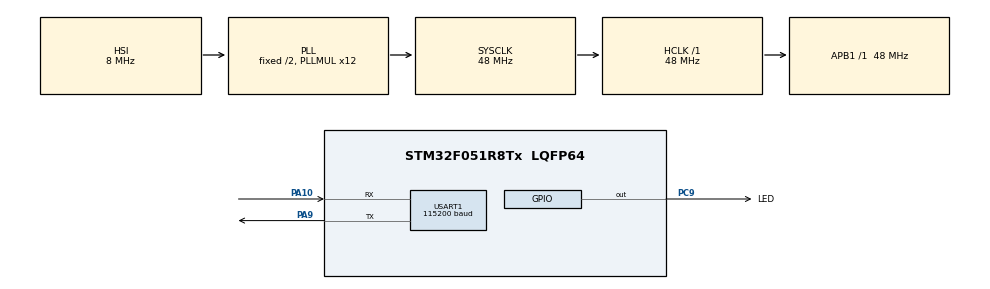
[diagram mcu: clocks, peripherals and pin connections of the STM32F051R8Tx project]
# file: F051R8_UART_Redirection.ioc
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Mcu.Family=STM32F0
PA10.Mode=Asynchronous
PC9.GPIO_Label=LED
USART1.BaudRate=115200
PA14.GPIO_Label=SWCLK
RCC.SYSCLKSource=RCC_SYSCLKSOURCE_PLLCLK
ProjectManager.StackSize=0x400
USART1.VirtualMode-Asynchronous=VM_ASYNC
PA13.Signal=SYS_SWDIO
PA9.Mode=Asynchronous
ProjectManager.TargetToolchain=STM32CubeIDE
RCC.HCLKFreq_Value=48000000
PA9.Signal=USART1_TX
RCC.AHBFreq_Value=48000000
board=STM32F0DISCOVERY
RCC.PLLMUL=RCC_PLL_MUL12
PA14.Mode=Serial_Wire
PA13.Mode=Serial_Wire
Mcu.Name=STM32F051R8Tx
PA13.GPIO_Label=SWDIO
RCC.SYSCLKFreq_VALUE=48000000
Mcu.Package=LQFP64
PA10.Signal=USART1_RX
PA14.Signal=SYS_SWCLK
ProjectManager.HeapSize=0x200
RCC.APB1TimFreq_Value=48000000
PC9.Signal=GPIO_Output
RCC.APB1Freq_Value=48000000

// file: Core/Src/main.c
/* USER CODE BEGIN Header */
/**
  ******************************************************************************
  * @file           : main.c
  * @brief          : Main program body
  ******************************************************************************
  * @attention
  *
  * <h2><center>&copy; Copyright (c) 2021 STMicroelectronics.
  * All rights reserved.</center></h2>
  *
  * This software component is licensed by ST under BSD 3-Clause license,
  * the "License"; You may not use this file except in compliance with the
  * License. You may obtain a copy of the License at:
  *                        opensource.org/licenses/BSD-3-Clause
  *
  ******************************************************************************
  */
/* USER CODE END Header */
#include "main.h"

/* USER CODE BEGIN Includes */
#include <stdio.h>
#include <string.h>
#include "uart_redirection.h"
/* USER CODE END Includes */

UART_HandleTypeDef huart1;

/* USER CODE BEGIN PV */
unsigned char counter = 0;
unsigned char max = 255;
/* USER CODE END PV */

void SystemClock_Config(void);
static void MX_GPIO_Init(void);
static void MX_USART1_UART_Init(void);

int main(void)
{
  /* USER CODE BEGIN 1 */
  int imax = 255;
  /* USER CODE END 1 */

  /* MCU Configuration--------------------------------------------------------*/

  /* Reset of all peripherals, Initializes the Flash interface and the Systick. */
  HAL_Init();

  /* Configure the system clock */
  SystemClock_Config();

  /* Initialize all configured peripherals */
  MX_GPIO_Init();
  MX_USART1_UART_Init();
  /* USER CODE BEGIN 2 */
  Set_UART_Redirection_Port(&huart1);
  /* USER CODE END 2 */

  /* Infinite loop */
  /* USER CODE BEGIN WHILE */
  printf("Set max counter: ");
  scanf("%d", &imax);
  max = (unsigned char)imax;
  printf("Count to %d\n\r", max);
  while (1) {
    printf("counter=%03d\n\r", counter++);
    if (counter > (char) max) {
      counter = 0;
    }
    HAL_GPIO_TogglePin(LED_GPIO_Port, LED_Pin);
    HAL_Delay(500);
    /* USER CODE END WHILE */

  }
}

void SystemClock_Config(void)
{
  RCC_OscInitTypeDef RCC_OscInitStruct = {0};
  RCC_ClkInitTypeDef RCC_ClkInitStruct = {0};
  RCC_PeriphCLKInitTypeDef PeriphClkInit = {0};

  /** Initializes the RCC Oscillators according to the specified parameters
  * in the RCC_OscInitTypeDef structure.
  */
  RCC_OscInitStruct.OscillatorType = RCC_OSCILLATORTYPE_HSI;
  RCC_OscInitStruct.HSIState = RCC_HSI_ON;
  RCC_OscInitStruct.HSICalibrationValue = RCC_HSICALIBRATION_DEFAULT;
  RCC_OscInitStruct.PLL.PLLState = RCC_PLL_ON;
  RCC_OscInitStruct.PLL.PLLSource = RCC_PLLSOURCE_HSI;
  RCC_OscInitStruct.PLL.PLLMUL = RCC_PLL_MUL12;
  RCC_OscInitStruct.PLL.PREDIV = RCC_PREDIV_DIV1;
  if (HAL_RCC_OscConfig(&RCC_OscInitStruct) != HAL_OK)
  {
    Error_Handler();
  }
  /** Initializes the CPU, AHB and APB buses clocks
  */
  RCC_ClkInitStruct.ClockType = RCC_CLOCKTYPE_HCLK|RCC_CLOCKTYPE_SYSCLK
                              |RCC_CLOCKTYPE_PCLK1;
  RCC_ClkInitStruct.SYSCLKSource = RCC_SYSCLKSOURCE_PLLCLK;
  RCC_ClkInitStruct.AHBCLKDivider = RCC_SYSCLK_DIV1;
  RCC_ClkInitStruct.APB1CLKDivider = RCC_HCLK_DIV1;

  if (HAL_RCC_ClockConfig(&RCC_ClkInitStruct, FLASH_LATENCY_1) != HAL_OK)
  {
    Error_Handler();
  }
  PeriphClkInit.PeriphClockSelection = RCC_PERIPHCLK_USART1;
  PeriphClkInit.Usart1ClockSelection = RCC_USART1CLKSOURCE_PCLK1;
  if (HAL_RCCEx_PeriphCLKConfig(&PeriphClkInit) != HAL_OK)
  {
    Error_Handler();
  }
}

static void MX_USART1_UART_Init(void)
{

  huart1.Instance = USART1;
  huart1.Init.BaudRate = 115200;
  huart1.Init.WordLength = UART_WORDLENGTH_8B;
  huart1.Init.StopBits = UART_STOPBITS_1;
  huart1.Init.Parity = UART_PARITY_NONE;
  huart1.Init.Mode = UART_MODE_TX_RX;
  huart1.Init.HwFlowCtl = UART_HWCONTROL_NONE;
  huart1.Init.OverSampling = UART_OVERSAMPLING_16;
  huart1.Init.OneBitSampling = UART_ONE_BIT_SAMPLE_DISABLE;
  huart1.AdvancedInit.AdvFeatureInit = UART_ADVFEATURE_NO_INIT;
  if (HAL_UART_Init(&huart1) != HAL_OK)
  {
    Error_Handler();
  }

}

static void MX_GPIO_Init(void)
{
  GPIO_InitTypeDef GPIO_InitStruct = {0};

  /* GPIO Ports Clock Enable */
  __HAL_RCC_GPIOC_CLK_ENABLE();
  __HAL_RCC_GPIOA_CLK_ENABLE();

  /*Configure GPIO pin Output Level */
  HAL_GPIO_WritePin(LED_GPIO_Port, LED_Pin, GPIO_PIN_RESET);

  /*Configure GPIO pin : LED_Pin */
  GPIO_InitStruct.Pin = LED_Pin;
  GPIO_InitStruct.Mode = GPIO_MODE_OUTPUT_PP;
  GPIO_InitStruct.Pull = GPIO_NOPULL;
  GPIO_InitStruct.Speed = GPIO_SPEED_FREQ_LOW;
  HAL_GPIO_Init(LED_GPIO_Port, &GPIO_InitStruct);

}

void Error_Handler(void)
{
  __disable_irq();
  while (1)
  {
  }
}

/************************ (C) COPYRIGHT STMicroelectronics *****END OF FILE****/
